VERSION ""

NS_ :

BS_:

BU_:

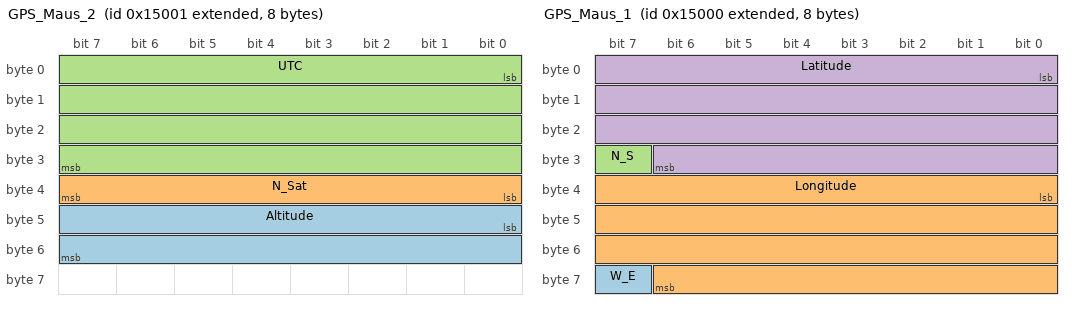
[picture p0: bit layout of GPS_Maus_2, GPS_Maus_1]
BO_ 2147569665 GPS_Maus_2: 8 Vector__XXX
 SG_ Altitude : 40|16@1- (1,0) [0|0] "" Vector__XXX
 SG_ N_Sat : 32|8@1- (1,0) [0|0] "" Vector__XXX
 SG_ UTC : 0|32@1+ (1,0) [0|0] "" Vector__XXX

BO_ 2147569664 GPS_Maus_1: 8 Vector__XXX
 SG_ W_E : 63|1@1- (1,0) [0|0] "" Vector__XXX
 SG_ Longitude : 32|31@1+ (0.0001,0) [0|0] "" Vector__XXX
 SG_ N_S : 31|1@1- (1,0) [0|0] "" Vector__XXX
 SG_ Latitude : 0|31@1+ (0.0001,0) [0|0] "" Vector__XXX

BA_DEF_  "BusType" STRING ;
BA_DEF_DEF_  "BusType" "CAN";
